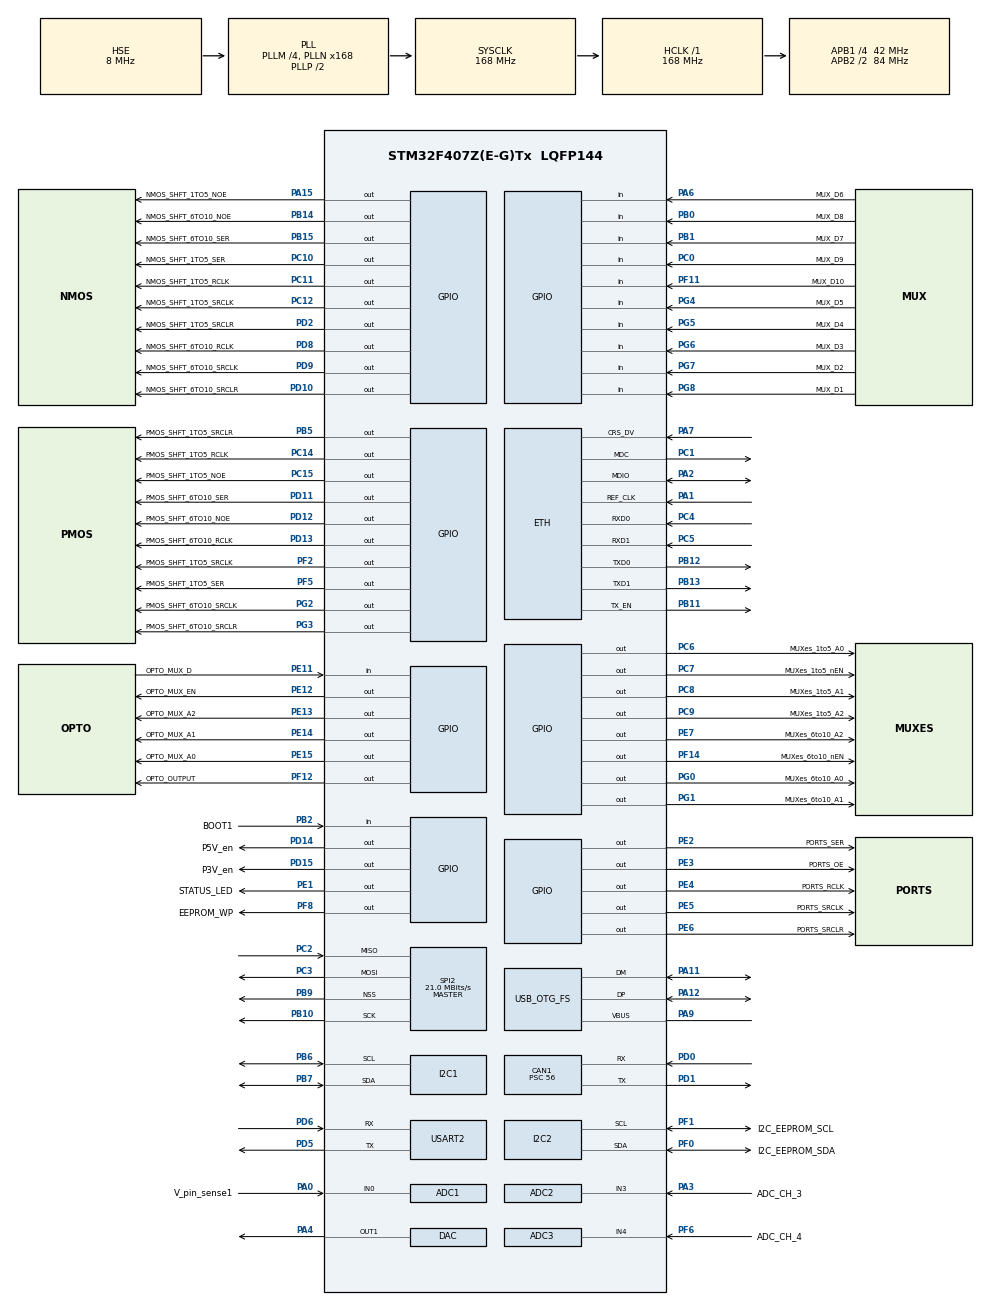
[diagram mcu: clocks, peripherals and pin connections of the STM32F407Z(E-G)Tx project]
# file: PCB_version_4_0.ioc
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ADC1.Channel-1\#ChannelRegularConversion=ADC_CHANNEL_0
ADC1.NbrOfConversionFlag=1
ADC1.Rank-1\#ChannelRegularConversion=1
ADC1.SamplingTime-1\#ChannelRegularConversion=ADC_SAMPLETIME_3CYCLES
ADC1.master=1
ADC2.Channel-2\#ChannelRegularConversion=ADC_CHANNEL_3
ADC2.NbrOfConversionFlag=1
ADC2.Rank-2\#ChannelRegularConversion=1
ADC2.SamplingTime-2\#ChannelRegularConversion=ADC_SAMPLETIME_3CYCLES
ADC3.Channel-1\#ChannelRegularConversion=ADC_CHANNEL_4
ADC3.NbrOfConversionFlag=1
ADC3.Rank-1\#ChannelRegularConversion=1
ADC3.SamplingTime-1\#ChannelRegularConversion=ADC_SAMPLETIME_3CYCLES
CAN1.CalculateBaudRate=249999
CAN1.CalculateTimeBit=4000
CAN1.CalculateTimeQuantum=1333.3333333333335
CAN1.Mode=CAN_MODE_LOOPBACK
CAN1.Prescaler=56
ETH.MACAddr=00\:80\:E1\:01\:23\:45
ETH.MediaInterface=HAL_ETH_RMII_MODE
ETH.PHY_Name_RMII=DP83848_PHY_ADDRESS
FREERTOS.Tasks01=defaultTask,0,8192,StartDefaultTask,Default,NULL,Dynamic,NULL,NULL
FREERTOS.configMINIMAL_STACK_SIZE=600
FREERTOS.configTOTAL_HEAP_SIZE=65536
FREERTOS.configUSE_NEWLIB_REENTRANT=1
LWIP.BSP.number=1
LWIP.CMSIS_VERSION-Enabled=1
LWIP.Version=v2.1.2_Cube
LWIP0.BSP.STBoard=false
LWIP0.BSP.api=BSP_COMPONENT_DRIVER
LWIP0.BSP.component=DP83848
LWIP0.BSP.instance=DP83848
LWIP0.BSP.name=Driver_PHY
LWIP0.BSP.semaphore=S_DP83848
LWIP0.BSP.solution=DP83848
Mcu.Family=STM32F4
Mcu.Name=STM32F407Z(E-G)Tx
Mcu.Package=LQFP144
NVIC.CAN1_RX0_IRQn=true\:5\:0\:false\:false\:true\:true\:true\:true\:true
NVIC.CAN1_RX1_IRQn=true\:5\:0\:false\:false\:true\:true\:true\:true\:true
NVIC.ETH_IRQn=true\:5\:0\:false\:false\:true\:true\:true\:true\:true
NVIC.OTG_FS_IRQn=true\:5\:0\:false\:false\:true\:true\:false\:true\:true
NVIC.PriorityGroup=NVIC_PRIORITYGROUP_4
NVIC.TIM1_TRG_COM_TIM11_IRQn=true\:5\:0\:false\:false\:true\:true\:true\:true\:true
NVIC.TIM8_TRG_COM_TIM14_IRQn=true\:15\:0\:false\:false\:true\:false\:false\:true\:true
NVIC.TimeBase=TIM8_TRG_COM_TIM14_IRQn
NVIC.TimeBaseIP=TIM14
PA0-WKUP.GPIO_Label=V_pin_sense1
PA0-WKUP.Signal=ADCx_IN0
PA1.Mode=RMII
PA1.Signal=ETH_REF_CLK
PA11.Mode=Device_Only
PA11.Signal=USB_OTG_FS_DM
PA12.Mode=Device_Only
PA12.Signal=USB_OTG_FS_DP
PA13.Mode=Trace_Asynchronous_SW
PA13.Signal=SYS_JTMS-SWDIO
PA14.Mode=Trace_Asynchronous_SW
PA14.Signal=SYS_JTCK-SWCLK
PA15.GPIO_Label=NMOS_SHFT_1TO5_NOE
PA15.Signal=GPIO_Output
PA2.Mode=RMII
PA2.Signal=ETH_MDIO
PA3.GPIO_Label=ADC_CH_3
PA3.Signal=ADCx_IN3
PA4.Signal=COMP_DAC1_group
PA6.GPIO_Label=MUX_D6
PA6.Signal=GPIO_Input
PA7.Mode=RMII
PA7.Signal=ETH_CRS_DV
PA9.Mode=Activate_VBUS
PA9.Signal=USB_OTG_FS_VBUS
PB0.GPIO_Label=MUX_D8
PB0.Signal=GPIO_Input
PB1.GPIO_Label=MUX_D7
PB1.Signal=GPIO_Input
PB10.Mode=Full_Duplex_Master
PB10.Signal=SPI2_SCK
PB11.Mode=RMII
PB11.Signal=ETH_TX_EN
PB12.Mode=RMII
PB12.Signal=ETH_TXD0
PB13.Mode=RMII
PB13.Signal=ETH_TXD1
PB14.GPIO_Label=NMOS_SHFT_6TO10_NOE
PB14.Signal=GPIO_Output
PB15.GPIO_Label=NMOS_SHFT_6TO10_SER
PB15.Signal=GPIO_Output
PB2.GPIO_Label=BOOT1
PB2.Signal=GPIO_Input
PB3.Mode=Trace_Asynchronous_SW
PB3.Signal=SYS_JTDO-SWO
PB5.GPIO_Label=PMOS_SHFT_1TO5_SRCLR
PB5.Signal=GPIO_Output
PB6.Mode=I2C
PB6.Signal=I2C1_SCL
PB7.Mode=I2C
PB7.Signal=I2C1_SDA
PB9.Mode=NSS_Signal_Hard_Output
PB9.Signal=SPI2_NSS
PC0.GPIO_Label=MUX_D9
PC0.Signal=GPIO_Input
PC1.Mode=RMII
PC1.Signal=ETH_MDC
PC10.GPIO_Label=NMOS_SHFT_1TO5_SER
PC10.Signal=GPIO_Output
PC11.GPIO_Label=NMOS_SHFT_1TO5_RCLK
PC11.Signal=GPIO_Output
PC12.GPIO_Label=NMOS_SHFT_1TO5_SRCLK
PC12.Signal=GPIO_Output
PC14-OSC32_IN.GPIO_Label=PMOS_SHFT_1TO5_RCLK
PC14-OSC32_IN.Signal=GPIO_Output
PC15-OSC32_OUT.GPIO_Label=PMOS_SHFT_1TO5_NOE
PC15-OSC32_OUT.Signal=GPIO_Output
PC2.Mode=Full_Duplex_Master
PC2.Signal=SPI2_MISO
PC3.Mode=Full_Duplex_Master
PC3.Signal=SPI2_MOSI
PC4.Mode=RMII
PC4.Signal=ETH_RXD0
PC5.Mode=RMII
PC5.Signal=ETH_RXD1
PC6.GPIO_Label=MUXes_1to5_A0
PC6.Signal=GPIO_Output
PC7.GPIO_Label=MUXes_1to5_nEN
PC7.Signal=GPIO_Output
PC8.GPIO_Label=MUXes_1to5_A1
PC8.Signal=GPIO_Output
PC9.GPIO_Label=MUXes_1to5_A2
PC9.Signal=GPIO_Output
PD0.GPIO_PuPd=GPIO_NOPULL
PD0.Mode=CAN_Activate
PD0.Signal=CAN1_RX
PD1.GPIO_PuPd=GPIO_NOPULL
PD1.Mode=CAN_Activate
PD1.Signal=CAN1_TX
PD10.GPIO_Label=NMOS_SHFT_6TO10_SRCLR
PD10.Signal=GPIO_Output
PD11.GPIO_Label=PMOS_SHFT_6TO10_SER
PD11.Signal=GPIO_Output
PD12.GPIO_Label=PMOS_SHFT_6TO10_NOE
PD12.Signal=GPIO_Output
PD13.GPIO_Label=PMOS_SHFT_6TO10_RCLK
PD13.Signal=GPIO_Output
PD14.GPIO_Label=P5V_en
PD14.Signal=GPIO_Output
PD15.GPIO_Label=P3V_en
PD15.Signal=GPIO_Output
PD2.GPIO_Label=NMOS_SHFT_1TO5_SRCLR
PD2.Signal=GPIO_Output
PD5.Mode=Asynchronous
PD5.Signal=USART2_TX
PD6.Mode=Asynchronous
PD6.Signal=USART2_RX
PD8.GPIO_Label=NMOS_SHFT_6TO10_RCLK
PD8.Signal=GPIO_Output
PD9.GPIO_Label=NMOS_SHFT_6TO10_SRCLK
PD9.Signal=GPIO_Output
PE1.GPIO_Label=STATUS_LED
PE1.Signal=GPIO_Output
PE11.GPIO_Label=OPTO_MUX_D
PE11.GPIO_PuPd=GPIO_NOPULL
PE11.Signal=GPIO_Input
PE12.GPIO_Label=OPTO_MUX_EN
PE12.GPIO_PuPd=GPIO_NOPULL
PE12.Signal=GPIO_Output
PE13.GPIO_Label=OPTO_MUX_A2
PE13.GPIO_Speed=GPIO_SPEED_FREQ_MEDIUM
PE13.Signal=GPIO_Output
PE14.GPIO_Label=OPTO_MUX_A1
PE14.GPIO_Speed=GPIO_SPEED_FREQ_MEDIUM
PE14.Signal=GPIO_Output
PE15.GPIO_Label=OPTO_MUX_A0
PE15.GPIO_Speed=GPIO_SPEED_FREQ_MEDIUM
PE15.Signal=GPIO_Output
PE2.GPIO_Label=PORTS_SER
PE2.Signal=GPIO_Output
PE3.GPIO_Label=PORTS_OE
PE3.Signal=GPIO_Output
PE4.GPIO_Label=PORTS_RCLK
PE4.Signal=GPIO_Output
PE5.GPIO_Label=PORTS_SRCLK
PE5.Signal=GPIO_Output
PE6.GPIO_Label=PORTS_SRCLR
PE6.Signal=GPIO_Output
PE7.GPIO_Label=MUXes_6to10_A2
PE7.Signal=GPIO_Output
PF0.GPIO_Label=I2C_EEPROM_SDA
PF0.Mode=I2C
PF0.Signal=I2C2_SDA
PF1.GPIO_Label=I2C_EEPROM_SCL
PF1.Mode=I2C
PF1.Signal=I2C2_SCL
PF11.GPIO_Label=MUX_D10
PF11.Signal=GPIO_Input
PF12.GPIO_Label=OPTO_OUTPUT
PF12.Signal=GPIO_Output
PF14.GPIO_Label=MUXes_6to10_nEN
PF14.Signal=GPIO_Output
PF2.GPIO_Label=PMOS_SHFT_1TO5_SRCLK
PF2.Signal=GPIO_Output
PF5.GPIO_Label=PMOS_SHFT_1TO5_SER
PF5.Signal=GPIO_Output
PF6.GPIO_Label=ADC_CH_4
PF6.Mode=IN4
PF6.Signal=ADC3_IN4
PF8.GPIO_Label=EEPROM_WP
PF8.Signal=GPIO_Output
PG0.GPIO_Label=MUXes_6to10_A0
PG0.Signal=GPIO_Output
PG1.GPIO_Label=MUXes_6to10_A1
PG1.Signal=GPIO_Output
PG2.GPIO_Label=PMOS_SHFT_6TO10_SRCLK
PG2.Signal=GPIO_Output
PG3.GPIO_Label=PMOS_SHFT_6TO10_SRCLR
PG3.Signal=GPIO_Output
PG4.GPIO_Label=MUX_D5
PG4.Signal=GPIO_Input
PG5.GPIO_Label=MUX_D4
PG5.Signal=GPIO_Input
PG6.GPIO_Label=MUX_D3
PG6.Signal=GPIO_Input
PG7.GPIO_Label=MUX_D2
PG7.Signal=GPIO_Input
PG8.GPIO_Label=MUX_D1
PG8.Signal=GPIO_Input
PH0-OSC_IN.Mode=HSE-External-Oscillator
PH0-OSC_IN.Signal=RCC_OSC_IN
PH1-OSC_OUT.Mode=HSE-External-Oscillator
PH1-OSC_OUT.Signal=RCC_OSC_OUT
ProjectManager.HeapSize=0x200
ProjectManager.StackSize=0x400
ProjectManager.TargetToolchain=Makefile
RCC.48MHZClocksFreq_Value=48000000
RCC.AHBFreq_Value=168000000
RCC.APB1CLKDivider=RCC_HCLK_DIV4
RCC.APB1Freq_Value=42000000
RCC.APB1TimFreq_Value=84000000
RCC.APB2CLKDivider=RCC_HCLK_DIV2
RCC.APB2Freq_Value=84000000
RCC.APB2TimFreq_Value=168000000
RCC.CortexFreq_Value=168000000
RCC.HCLKFreq_Value=168000000
RCC.HSE_VALUE=8000000
RCC.HSI_VALUE=16000000
RCC.LSE_VALUE=32768
RCC.PLLM=4
RCC.PLLN=168
RCC.PLLQ=7
RCC.RCC_RTC_Clock_Source=RCC_RTCCLKSOURCE_LSE
RCC.RCC_RTC_Clock_SourceVirtual=RCC_RTCCLKSOURCE_LSE
RCC.RCC_RTC_Clock_Source_FROM_HSE=RCC_RTCCLKSOURCE_HSE_DIV9
RCC.SYSCLKFreq_VALUE=168000000
RCC.SYSCLKSource=RCC_SYSCLKSOURCE_PLLCLK
RCC.VCOOutputFreq_Value=336000000
SH.ADCx_IN0.0=ADC1_IN0,IN0
SH.ADCx_IN3.0=ADC2_IN3,IN3
SH.COMP_DAC1_group.0=DAC_OUT1,DAC_OUT1
SPI2.BaudRatePrescaler=SPI_BAUDRATEPRESCALER_2
SPI2.CalculateBaudRate=21.0 MBits/s
SPI2.Direction=SPI_DIRECTION_2LINES
SPI2.Mode=SPI_MODE_MASTER
SPI2.VirtualNSS=VM_NSSHARD
SPI2.VirtualType=VM_MASTER
TIM11.AutoReloadPreload=TIM_AUTORELOAD_PRELOAD_ENABLE
TIM11.Period=240-1
USART2.VirtualMode=VM_ASYNC
USB_DEVICE.CLASS_NAME_FS=CDC
USB_DEVICE.VirtualMode-CDC_FS=Cdc
USB_DEVICE.VirtualModeFS=Cdc_FS
USB_OTG_FS.VirtualMode=Device_Only
VP_FREERTOS_VS_CMSIS_V1.Mode=CMSIS_V1
VP_LWIP_VS_Enabled.Mode=Enabled
VP_SYS_VS_tim14.Mode=TIM14
VP_TIM11_VS_ClockSourceINT.Mode=Enable_Timer
VP_USB_DEVICE_VS_USB_DEVICE_CDC_FS.Mode=CDC_FS
board=custom

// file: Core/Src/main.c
/* USER CODE BEGIN Header */
/**
  ******************************************************************************
  * @file           : main.c
  * @brief          : Main program body
  ******************************************************************************
  * @attention
  *
  * Copyright (c) 2023 STMicroelectronics.
  * All rights reserved.
  *
  * This software is licensed under terms that can be found in the LICENSE file
  * in the root directory of this software component.
  * If no LICENSE file comes with this software, it is provided AS-IS.
  *
  ******************************************************************************
  */
/* USER CODE END Header */
#include "main.h"
#include "cmsis_os.h"
#include "lwip.h"
#include "usb_device.h"

/* USER CODE BEGIN Includes */
#include "usbd_cdc_if.h"
#include "stdio.h"
#include "tcpserver.h"
#include "globals.h"
/* USER CODE END Includes */

/* USER CODE BEGIN PM */
CAN_TxHeaderTypeDef CanTxHeader;
CAN_RxHeaderTypeDef CanRxHeader;
uint32_t CanTxMailbox;
uint8_t CanTxData[8];
uint8_t CanRxData[8];

HAL_StatusTypeDef status;
uint32_t Reg_Val;

/* USER CODE END PM */

ADC_HandleTypeDef hadc1;
ADC_HandleTypeDef hadc2;
ADC_HandleTypeDef hadc3;

CAN_HandleTypeDef hcan1;

DAC_HandleTypeDef hdac;

I2C_HandleTypeDef hi2c1;
I2C_HandleTypeDef hi2c2;

SPI_HandleTypeDef hspi2;

TIM_HandleTypeDef htim11;

UART_HandleTypeDef huart2;

osThreadId defaultTaskHandle;
/* USER CODE BEGIN PV */
extern int tcpecho_init();

/* USER CODE END PV */

void SystemClock_Config(void);
static void MX_GPIO_Init(void);
static void MX_ADC1_Init(void);
static void MX_ADC2_Init(void);
static void MX_DAC_Init(void);
static void MX_SPI2_Init(void);
static void MX_ADC3_Init(void);
static void MX_CAN1_Init(void);
static void MX_I2C1_Init(void);
static void MX_USART2_UART_Init(void);
static void MX_I2C2_Init(void);
static void MX_TIM11_Init(void);
void StartDefaultTask(void const * argument);

/* USER CODE BEGIN PFP */
//Redriect printf to USB CDC
int _write(int file, char *ptr, int len)
{
  CDC_Transmit_FS((uint8_t*)ptr, len);
  return len;
}

//overide HAL_CAN_RxFifo0MsgPendingCallback
__weak void HAL_CAN_RxFifo0MsgPendingCallback(CAN_HandleTypeDef *hcan)
{
  printf("CAN RX Callback\n");
}

/* USER CODE END PFP */

int main(void)
{

  /* MCU Configuration--------------------------------------------------------*/

  /* Reset of all peripherals, Initializes the Flash interface and the Systick. */
  HAL_Init();

  /* Configure the system clock */
  SystemClock_Config();

  /* Initialize all configured peripherals */
  MX_GPIO_Init();
  MX_ADC1_Init();
  MX_ADC2_Init();
  MX_DAC_Init();
  MX_SPI2_Init();
  MX_ADC3_Init();
  MX_CAN1_Init();
  MX_I2C1_Init();
  MX_USART2_UART_Init();
  MX_I2C2_Init();
  MX_TIM11_Init();
  /* USER CODE BEGIN 2 */
  HAL_TIM_Base_Start_IT(&htim11);
  /* USER CODE END 2 */

  /* Create the thread(s) */
  /* definition and creation of defaultTask */
  osThreadDef(defaultTask, StartDefaultTask, osPriorityNormal, 0, 8192);
  defaultTaskHandle = osThreadCreate(osThread(defaultTask), NULL);

  /* Start scheduler */
  osKernelStart();
  /* We should never get here as control is now taken by the scheduler */
  /* Infinite loop */
  while (1)
  {

  }
}

void SystemClock_Config(void)
{
  RCC_OscInitTypeDef RCC_OscInitStruct = {0};
  RCC_ClkInitTypeDef RCC_ClkInitStruct = {0};

  /** Configure the main internal regulator output voltage
  */
  __HAL_RCC_PWR_CLK_ENABLE();
  __HAL_PWR_VOLTAGESCALING_CONFIG(PWR_REGULATOR_VOLTAGE_SCALE1);

  /** Initializes the RCC Oscillators according to the specified parameters
  * in the RCC_OscInitTypeDef structure.
  */
  RCC_OscInitStruct.OscillatorType = RCC_OSCILLATORTYPE_HSE;
  RCC_OscInitStruct.HSEState = RCC_HSE_ON;
  RCC_OscInitStruct.PLL.PLLState = RCC_PLL_ON;
  RCC_OscInitStruct.PLL.PLLSource = RCC_PLLSOURCE_HSE;
  RCC_OscInitStruct.PLL.PLLM = 4;
  RCC_OscInitStruct.PLL.PLLN = 168;
  RCC_OscInitStruct.PLL.PLLP = RCC_PLLP_DIV2;
  RCC_OscInitStruct.PLL.PLLQ = 7;
  if (HAL_RCC_OscConfig(&RCC_OscInitStruct) != HAL_OK)
  {
    Error_Handler();
  }

  /** Initializes the CPU, AHB and APB buses clocks
  */
  RCC_ClkInitStruct.ClockType = RCC_CLOCKTYPE_HCLK|RCC_CLOCKTYPE_SYSCLK
                              |RCC_CLOCKTYPE_PCLK1|RCC_CLOCKTYPE_PCLK2;
  RCC_ClkInitStruct.SYSCLKSource = RCC_SYSCLKSOURCE_PLLCLK;
  RCC_ClkInitStruct.AHBCLKDivider = RCC_SYSCLK_DIV1;
  RCC_ClkInitStruct.APB1CLKDivider = RCC_HCLK_DIV4;
  RCC_ClkInitStruct.APB2CLKDivider = RCC_HCLK_DIV2;

  if (HAL_RCC_ClockConfig(&RCC_ClkInitStruct, FLASH_LATENCY_5) != HAL_OK)
  {
    Error_Handler();
  }
}

static void MX_ADC1_Init(void)
{

  ADC_ChannelConfTypeDef sConfig = {0};

  /** Configure the global features of the ADC (Clock, Resolution, Data Alignment and number of conversion)
  */
  hadc1.Instance = ADC1;
  hadc1.Init.ClockPrescaler = ADC_CLOCK_SYNC_PCLK_DIV4;
  hadc1.Init.Resolution = ADC_RESOLUTION_12B;
  hadc1.Init.ScanConvMode = DISABLE;
  hadc1.Init.ContinuousConvMode = DISABLE;
  hadc1.Init.DiscontinuousConvMode = DISABLE;
  hadc1.Init.ExternalTrigConvEdge = ADC_EXTERNALTRIGCONVEDGE_NONE;
  hadc1.Init.ExternalTrigConv = ADC_SOFTWARE_START;
  hadc1.Init.DataAlign = ADC_DATAALIGN_RIGHT;
  hadc1.Init.NbrOfConversion = 1;
  hadc1.Init.DMAContinuousRequests = DISABLE;
  hadc1.Init.EOCSelection = ADC_EOC_SINGLE_CONV;
  if (HAL_ADC_Init(&hadc1) != HAL_OK)
  {
    Error_Handler();
  }

  /** Configure for the selected ADC regular channel its corresponding rank in the sequencer and its sample time.
  */
  sConfig.Channel = ADC_CHANNEL_0;
  sConfig.Rank = 1;
  sConfig.SamplingTime = ADC_SAMPLETIME_3CYCLES;
  if (HAL_ADC_ConfigChannel(&hadc1, &sConfig) != HAL_OK)
  {
    Error_Handler();
  }

}

static void MX_ADC2_Init(void)
{

  ADC_ChannelConfTypeDef sConfig = {0};

  /** Configure the global features of the ADC (Clock, Resolution, Data Alignment and number of conversion)
  */
  hadc2.Instance = ADC2;
  hadc2.Init.ClockPrescaler = ADC_CLOCK_SYNC_PCLK_DIV4;
  hadc2.Init.Resolution = ADC_RESOLUTION_12B;
  hadc2.Init.ScanConvMode = DISABLE;
  hadc2.Init.ContinuousConvMode = DISABLE;
  hadc2.Init.DiscontinuousConvMode = DISABLE;
  hadc2.Init.ExternalTrigConvEdge = ADC_EXTERNALTRIGCONVEDGE_NONE;
  hadc2.Init.ExternalTrigConv = ADC_SOFTWARE_START;
  hadc2.Init.DataAlign = ADC_DATAALIGN_RIGHT;
  hadc2.Init.NbrOfConversion = 1;
  hadc2.Init.DMAContinuousRequests = DISABLE;
  hadc2.Init.EOCSelection = ADC_EOC_SINGLE_CONV;
  if (HAL_ADC_Init(&hadc2) != HAL_OK)
  {
    Error_Handler();
  }

  /** Configure for the selected ADC regular channel its corresponding rank in the sequencer and its sample time.
  */
  sConfig.Channel = ADC_CHANNEL_3;
  sConfig.Rank = 1;
  sConfig.SamplingTime = ADC_SAMPLETIME_3CYCLES;
  if (HAL_ADC_ConfigChannel(&hadc2, &sConfig) != HAL_OK)
  {
    Error_Handler();
  }

}

static void MX_ADC3_Init(void)
{

  ADC_ChannelConfTypeDef sConfig = {0};

  /** Configure the global features of the ADC (Clock, Resolution, Data Alignment and number of conversion)
  */
  hadc3.Instance = ADC3;
  hadc3.Init.ClockPrescaler = ADC_CLOCK_SYNC_PCLK_DIV4;
  hadc3.Init.Resolution = ADC_RESOLUTION_12B;
  hadc3.Init.ScanConvMode = DISABLE;
  hadc3.Init.ContinuousConvMode = DISABLE;
  hadc3.Init.DiscontinuousConvMode = DISABLE;
  hadc3.Init.ExternalTrigConvEdge = ADC_EXTERNALTRIGCONVEDGE_NONE;
  hadc3.Init.ExternalTrigConv = ADC_SOFTWARE_START;
  hadc3.Init.DataAlign = ADC_DATAALIGN_RIGHT;
  hadc3.Init.NbrOfConversion = 1;
  hadc3.Init.DMAContinuousRequests = DISABLE;
  hadc3.Init.EOCSelection = ADC_EOC_SINGLE_CONV;
  if (HAL_ADC_Init(&hadc3) != HAL_OK)
  {
    Error_Handler();
  }

  /** Configure for the selected ADC regular channel its corresponding rank in the sequencer and its sample time.
  */
  sConfig.Channel = ADC_CHANNEL_4;
  sConfig.Rank = 1;
  sConfig.SamplingTime = ADC_SAMPLETIME_3CYCLES;
  if (HAL_ADC_ConfigChannel(&hadc3, &sConfig) != HAL_OK)
  {
    Error_Handler();
  }

}

static void MX_CAN1_Init(void)
{

  hcan1.Instance = CAN1;
  hcan1.Init.Prescaler = 56;
  hcan1.Init.Mode = CAN_MODE_LOOPBACK;
  hcan1.Init.SyncJumpWidth = CAN_SJW_1TQ;
  hcan1.Init.TimeSeg1 = CAN_BS1_1TQ;
  hcan1.Init.TimeSeg2 = CAN_BS2_1TQ;
  hcan1.Init.TimeTriggeredMode = DISABLE;
  hcan1.Init.AutoBusOff = DISABLE;
  hcan1.Init.AutoWakeUp = DISABLE;
  hcan1.Init.AutoRetransmission = DISABLE;
  hcan1.Init.ReceiveFifoLocked = DISABLE;
  hcan1.Init.TransmitFifoPriority = DISABLE;
  if (HAL_CAN_Init(&hcan1) != HAL_OK)
  {
    Error_Handler();
  }
  /* USER CODE BEGIN CAN1_Init 2 */
  CAN_FilterTypeDef canFilterConfig;
  canFilterConfig.FilterActivation = CAN_FILTER_ENABLE;
  canFilterConfig.FilterBank = 10;  // anything between 0 to SlaveStartFilterBank
  canFilterConfig.FilterFIFOAssignment = CAN_RX_FIFO0;
  canFilterConfig.FilterIdHigh = 0;
  canFilterConfig.FilterIdLow = 0x0;
  canFilterConfig.FilterMaskIdHigh = 0x0;
  canFilterConfig.FilterMaskIdLow = 0x0000;
  canFilterConfig.FilterMode = CAN_FILTERMODE_IDMASK;
  canFilterConfig.FilterScale = CAN_FILTERSCALE_32BIT;
  canFilterConfig.SlaveStartFilterBank = 0;  // 13 to 27 are assigned to slave CAN (CAN 2) OR 0 to 12 are assgned to CAN1

  HAL_CAN_ConfigFilter(&hcan1, &canFilterConfig);

  /* USER CODE END CAN1_Init 2 */

}

static void MX_DAC_Init(void)
{

  DAC_ChannelConfTypeDef sConfig = {0};

  /** DAC Initialization
  */
  hdac.Instance = DAC;
  if (HAL_DAC_Init(&hdac) != HAL_OK)
  {
    Error_Handler();
  }

  /** DAC channel OUT1 config
  */
  sConfig.DAC_Trigger = DAC_TRIGGER_NONE;
  sConfig.DAC_OutputBuffer = DAC_OUTPUTBUFFER_ENABLE;
  if (HAL_DAC_ConfigChannel(&hdac, &sConfig, DAC_CHANNEL_1) != HAL_OK)
  {
    Error_Handler();
  }
  /* USER CODE BEGIN DAC_Init 2 */
  HAL_DAC_Start(&hdac, DAC_CHANNEL_1);
  /* USER CODE END DAC_Init 2 */

}

static void MX_I2C1_Init(void)
{

  hi2c1.Instance = I2C1;
  hi2c1.Init.ClockSpeed = 100000;
  hi2c1.Init.DutyCycle = I2C_DUTYCYCLE_2;
  hi2c1.Init.OwnAddress1 = 0;
  hi2c1.Init.AddressingMode = I2C_ADDRESSINGMODE_7BIT;
  hi2c1.Init.DualAddressMode = I2C_DUALADDRESS_DISABLE;
  hi2c1.Init.OwnAddress2 = 0;
  hi2c1.Init.GeneralCallMode = I2C_GENERALCALL_DISABLE;
  hi2c1.Init.NoStretchMode = I2C_NOSTRETCH_DISABLE;
  if (HAL_I2C_Init(&hi2c1) != HAL_OK)
  {
    Error_Handler();
  }

}

static void MX_I2C2_Init(void)
{

  hi2c2.Instance = I2C2;
  hi2c2.Init.ClockSpeed = 100000;
  hi2c2.Init.DutyCycle = I2C_DUTYCYCLE_2;
  hi2c2.Init.OwnAddress1 = 0;
  hi2c2.Init.AddressingMode = I2C_ADDRESSINGMODE_7BIT;
  hi2c2.Init.DualAddressMode = I2C_DUALADDRESS_DISABLE;
  hi2c2.Init.OwnAddress2 = 0;
  hi2c2.Init.GeneralCallMode = I2C_GENERALCALL_DISABLE;
  hi2c2.Init.NoStretchMode = I2C_NOSTRETCH_DISABLE;
  if (HAL_I2C_Init(&hi2c2) != HAL_OK)
  {
    Error_Handler();
  }

}

static void MX_SPI2_Init(void)
{

  /* SPI2 parameter configuration*/
  hspi2.Instance = SPI2;
  hspi2.Init.Mode = SPI_MODE_MASTER;
  hspi2.Init.Direction = SPI_DIRECTION_2LINES;
  hspi2.Init.DataSize = SPI_DATASIZE_8BIT;
  hspi2.Init.CLKPolarity = SPI_POLARITY_LOW;
  hspi2.Init.CLKPhase = SPI_PHASE_1EDGE;
  hspi2.Init.NSS = SPI_NSS_HARD_OUTPUT;
  hspi2.Init.BaudRatePrescaler = SPI_BAUDRATEPRESCALER_2;
  hspi2.Init.FirstBit = SPI_FIRSTBIT_MSB;
  hspi2.Init.TIMode = SPI_TIMODE_DISABLE;
  hspi2.Init.CRCCalculation = SPI_CRCCALCULATION_DISABLE;
  hspi2.Init.CRCPolynomial = 10;
  if (HAL_SPI_Init(&hspi2) != HAL_OK)
  {
    Error_Handler();
  }

}

static void MX_TIM11_Init(void)
{

  htim11.Instance = TIM11;
  htim11.Init.Prescaler = 0;
  htim11.Init.CounterMode = TIM_COUNTERMODE_UP;
  htim11.Init.Period = 240-1;
  htim11.Init.ClockDivision = TIM_CLOCKDIVISION_DIV1;
  htim11.Init.AutoReloadPreload = TIM_AUTORELOAD_PRELOAD_ENABLE;
  if (HAL_TIM_Base_Init(&htim11) != HAL_OK)
  {
    Error_Handler();
  }

}

static void MX_USART2_UART_Init(void)
{

  huart2.Instance = USART2;
  huart2.Init.BaudRate = 115200;
  huart2.Init.WordLength = UART_WORDLENGTH_8B;
  huart2.Init.StopBits = UART_STOPBITS_1;
  huart2.Init.Parity = UART_PARITY_NONE;
  huart2.Init.Mode = UART_MODE_TX_RX;
  huart2.Init.HwFlowCtl = UART_HWCONTROL_NONE;
  huart2.Init.OverSampling = UART_OVERSAMPLING_16;
  if (HAL_UART_Init(&huart2) != HAL_OK)
  {
    Error_Handler();
  }

}

static void MX_GPIO_Init(void)
{
  GPIO_InitTypeDef GPIO_InitStruct = {0};

  /* GPIO Ports Clock Enable */
  __HAL_RCC_GPIOE_CLK_ENABLE();
  __HAL_RCC_GPIOC_CLK_ENABLE();
  __HAL_RCC_GPIOF_CLK_ENABLE();
  __HAL_RCC_GPIOH_CLK_ENABLE();
  __HAL_RCC_GPIOA_CLK_ENABLE();
  __HAL_RCC_GPIOB_CLK_ENABLE();
  __HAL_RCC_GPIOG_CLK_ENABLE();
  __HAL_RCC_GPIOD_CLK_ENABLE();

  /*Configure GPIO pin Output Level */
  HAL_GPIO_WritePin(GPIOE, PORTS_SER_Pin|PORTS_OE_Pin|PORTS_RCLK_Pin|PORTS_SRCLK_Pin
                          |PORTS_SRCLR_Pin|MUXes_6to10_A2_Pin|OPTO_MUX_EN_Pin|OPTO_MUX_A2_Pin
                          |OPTO_MUX_A1_Pin|OPTO_MUX_A0_Pin|STATUS_LED_Pin, GPIO_PIN_RESET);

  /*Configure GPIO pin Output Level */
  HAL_GPIO_WritePin(GPIOC, PMOS_SHFT_1TO5_RCLK_Pin|PMOS_SHFT_1TO5_NOE_Pin|MUXes_1to5_A0_Pin|MUXes_1to5_nEN_Pin
                          |MUXes_1to5_A1_Pin|MUXes_1to5_A2_Pin|NMOS_SHFT_1TO5_SER_Pin|NMOS_SHFT_1TO5_RCLK_Pin
                          |NMOS_SHFT_1TO5_SRCLK_Pin, GPIO_PIN_RESET);

  /*Configure GPIO pin Output Level */
  HAL_GPIO_WritePin(GPIOF, PMOS_SHFT_1TO5_SRCLK_Pin|PMOS_SHFT_1TO5_SER_Pin|EEPROM_WP_Pin|OPTO_OUTPUT_Pin
                          |MUXes_6to10_nEN_Pin, GPIO_PIN_RESET);

  /*Configure GPIO pin Output Level */
  HAL_GPIO_WritePin(GPIOG, MUXes_6to10_A0_Pin|MUXes_6to10_A1_Pin|PMOS_SHFT_6TO10_SRCLK_Pin|PMOS_SHFT_6TO10_SRCLR_Pin, GPIO_PIN_RESET);

  /*Configure GPIO pin Output Level */
  HAL_GPIO_WritePin(GPIOB, NMOS_SHFT_6TO10_NOE_Pin|NMOS_SHFT_6TO10_SER_Pin|PMOS_SHFT_1TO5_SRCLR_Pin, GPIO_PIN_RESET);

  /*Configure GPIO pin Output Level */
  HAL_GPIO_WritePin(GPIOD, NMOS_SHFT_6TO10_RCLK_Pin|NMOS_SHFT_6TO10_SRCLK_Pin|NMOS_SHFT_6TO10_SRCLR_Pin|PMOS_SHFT_6TO10_SER_Pin
                          |PMOS_SHFT_6TO10_NOE_Pin|PMOS_SHFT_6TO10_RCLK_Pin|P5V_en_Pin|P3V_en_Pin
                          |NMOS_SHFT_1TO5_SRCLR_Pin, GPIO_PIN_RESET);

  /*Configure GPIO pin Output Level */
  HAL_GPIO_WritePin(NMOS_SHFT_1TO5_NOE_GPIO_Port, NMOS_SHFT_1TO5_NOE_Pin, GPIO_PIN_RESET);

  /*Configure GPIO pins : PORTS_SER_Pin PORTS_OE_Pin PORTS_RCLK_Pin PORTS_SRCLK_Pin
                           PORTS_SRCLR_Pin MUXes_6to10_A2_Pin OPTO_MUX_EN_Pin STATUS_LED_Pin */
  GPIO_InitStruct.Pin = PORTS_SER_Pin|PORTS_OE_Pin|PORTS_RCLK_Pin|PORTS_SRCLK_Pin
                          |PORTS_SRCLR_Pin|MUXes_6to10_A2_Pin|OPTO_MUX_EN_Pin|STATUS_LED_Pin;
  GPIO_InitStruct.Mode = GPIO_MODE_OUTPUT_PP;
  GPIO_InitStruct.Pull = GPIO_NOPULL;
  GPIO_InitStruct.Speed = GPIO_SPEED_FREQ_LOW;
  HAL_GPIO_Init(GPIOE, &GPIO_InitStruct);

  /*Configure GPIO pins : PMOS_SHFT_1TO5_RCLK_Pin PMOS_SHFT_1TO5_NOE_Pin MUXes_1to5_A0_Pin MUXes_1to5_nEN_Pin
                           MUXes_1to5_A1_Pin MUXes_1to5_A2_Pin NMOS_SHFT_1TO5_SER_Pin NMOS_SHFT_1TO5_RCLK_Pin
                           NMOS_SHFT_1TO5_SRCLK_Pin */
  GPIO_InitStruct.Pin = PMOS_SHFT_1TO5_RCLK_Pin|PMOS_SHFT_1TO5_NOE_Pin|MUXes_1to5_A0_Pin|MUXes_1to5_nEN_Pin
                          |MUXes_1to5_A1_Pin|MUXes_1to5_A2_Pin|NMOS_SHFT_1TO5_SER_Pin|NMOS_SHFT_1TO5_RCLK_Pin
                          |NMOS_SHFT_1TO5_SRCLK_Pin;
  GPIO_InitStruct.Mode = GPIO_MODE_OUTPUT_PP;
  GPIO_InitStruct.Pull = GPIO_NOPULL;
  GPIO_InitStruct.Speed = GPIO_SPEED_FREQ_LOW;
  HAL_GPIO_Init(GPIOC, &GPIO_InitStruct);

  /*Configure GPIO pins : PMOS_SHFT_1TO5_SRCLK_Pin PMOS_SHFT_1TO5_SER_Pin EEPROM_WP_Pin OPTO_OUTPUT_Pin
                           MUXes_6to10_nEN_Pin */
  GPIO_InitStruct.Pin = PMOS_SHFT_1TO5_SRCLK_Pin|PMOS_SHFT_1TO5_SER_Pin|EEPROM_WP_Pin|OPTO_OUTPUT_Pin
                          |MUXes_6to10_nEN_Pin;
  GPIO_InitStruct.Mode = GPIO_MODE_OUTPUT_PP;
  GPIO_InitStruct.Pull = GPIO_NOPULL;
  GPIO_InitStruct.Speed = GPIO_SPEED_FREQ_LOW;
  HAL_GPIO_Init(GPIOF, &GPIO_InitStruct);

  /*Configure GPIO pin : MUX_D9_Pin */
  GPIO_InitStruct.Pin = MUX_D9_Pin;
  GPIO_InitStruct.Mode = GPIO_MODE_INPUT;
  GPIO_InitStruct.Pull = GPIO_NOPULL;
  HAL_GPIO_Init(MUX_D9_GPIO_Port, &GPIO_InitStruct);

  /*Configure GPIO pin : MUX_D6_Pin */
  GPIO_InitStruct.Pin = MUX_D6_Pin;
  GPIO_InitStruct.Mode = GPIO_MODE_INPUT;
  GPIO_InitStruct.Pull = GPIO_NOPULL;
  HAL_GPIO_Init(MUX_D6_GPIO_Port, &GPIO_InitStruct);

  /*Configure GPIO pins : MUX_D8_Pin MUX_D7_Pin BOOT1_Pin */
  GPIO_InitStruct.Pin = MUX_D8_Pin|MUX_D7_Pin|BOOT1_Pin;
  GPIO_InitStruct.Mode = GPIO_MODE_INPUT;
  GPIO_InitStruct.Pull = GPIO_NOPULL;
  HAL_GPIO_Init(GPIOB, &GPIO_InitStruct);

  /*Configure GPIO pin : MUX_D10_Pin */
  GPIO_InitStruct.Pin = MUX_D10_Pin;
  GPIO_InitStruct.Mode = GPIO_MODE_INPUT;
  GPIO_InitStruct.Pull = GPIO_NOPULL;
  HAL_GPIO_Init(MUX_D10_GPIO_Port, &GPIO_InitStruct);

  /*Configure GPIO pins : MUXes_6to10_A0_Pin MUXes_6to10_A1_Pin PMOS_SHFT_6TO10_SRCLK_Pin PMOS_SHFT_6TO10_SRCLR_Pin */
  GPIO_InitStruct.Pin = MUXes_6to10_A0_Pin|MUXes_6to10_A1_Pin|PMOS_SHFT_6TO10_SRCLK_Pin|PMOS_SHFT_6TO10_SRCLR_Pin;
  GPIO_InitStruct.Mode = GPIO_MODE_OUTPUT_PP;
  GPIO_InitStruct.Pull = GPIO_NOPULL;
  GPIO_InitStruct.Speed = GPIO_SPEED_FREQ_LOW;
  HAL_GPIO_Init(GPIOG, &GPIO_InitStruct);

  /*Configure GPIO pin : OPTO_MUX_D_Pin */
  GPIO_InitStruct.Pin = OPTO_MUX_D_Pin;
  GPIO_InitStruct.Mode = GPIO_MODE_INPUT;
  GPIO_InitStruct.Pull = GPIO_NOPULL;
  HAL_GPIO_Init(OPTO_MUX_D_GPIO_Port, &GPIO_InitStruct);

  /*Configure GPIO pins : OPTO_MUX_A2_Pin OPTO_MUX_A1_Pin OPTO_MUX_A0_Pin */
  GPIO_InitStruct.Pin = OPTO_MUX_A2_Pin|OPTO_MUX_A1_Pin|OPTO_MUX_A0_Pin;
  GPIO_InitStruct.Mode = GPIO_MODE_OUTPUT_PP;
  GPIO_InitStruct.Pull = GPIO_NOPULL;
  GPIO_InitStruct.Speed = GPIO_SPEED_FREQ_MEDIUM;
  HAL_GPIO_Init(GPIOE, &GPIO_InitStruct);

  /*Configure GPIO pins : NMOS_SHFT_6TO10_NOE_Pin NMOS_SHFT_6TO10_SER_Pin PMOS_SHFT_1TO5_SRCLR_Pin */
  GPIO_InitStruct.Pin = NMOS_SHFT_6TO10_NOE_Pin|NMOS_SHFT_6TO10_SER_Pin|PMOS_SHFT_1TO5_SRCLR_Pin;
  GPIO_InitStruct.Mode = GPIO_MODE_OUTPUT_PP;
  GPIO_InitStruct.Pull = GPIO_NOPULL;
  GPIO_InitStruct.Speed = GPIO_SPEED_FREQ_LOW;
  HAL_GPIO_Init(GPIOB, &GPIO_InitStruct);

  /*Configure GPIO pins : NMOS_SHFT_6TO10_RCLK_Pin NMOS_SHFT_6TO10_SRCLK_Pin NMOS_SHFT_6TO10_SRCLR_Pin PMOS_SHFT_6TO10_SER_Pin
                           PMOS_SHFT_6TO10_NOE_Pin PMOS_SHFT_6TO10_RCLK_Pin P5V_en_Pin P3V_en_Pin
                           NMOS_SHFT_1TO5_SRCLR_Pin */
  GPIO_InitStruct.Pin = NMOS_SHFT_6TO10_RCLK_Pin|NMOS_SHFT_6TO10_SRCLK_Pin|NMOS_SHFT_6TO10_SRCLR_Pin|PMOS_SHFT_6TO10_SER_Pin
                          |PMOS_SHFT_6TO10_NOE_Pin|PMOS_SHFT_6TO10_RCLK_Pin|P5V_en_Pin|P3V_en_Pin
                          |NMOS_SHFT_1TO5_SRCLR_Pin;
  GPIO_InitStruct.Mode = GPIO_MODE_OUTPUT_PP;
  GPIO_InitStruct.Pull = GPIO_NOPULL;
  GPIO_InitStruct.Speed = GPIO_SPEED_FREQ_LOW;
  HAL_GPIO_Init(GPIOD, &GPIO_InitStruct);

  /*Configure GPIO pins : MUX_D5_Pin MUX_D4_Pin MUX_D3_Pin MUX_D2_Pin
                           MUX_D1_Pin */
  GPIO_InitStruct.Pin = MUX_D5_Pin|MUX_D4_Pin|MUX_D3_Pin|MUX_D2_Pin
                          |MUX_D1_Pin;
  GPIO_InitStruct.Mode = GPIO_MODE_INPUT;
  GPIO_InitStruct.Pull = GPIO_NOPULL;
  HAL_GPIO_Init(GPIOG, &GPIO_InitStruct);

  /*Configure GPIO pin : NMOS_SHFT_1TO5_NOE_Pin */
  GPIO_InitStruct.Pin = NMOS_SHFT_1TO5_NOE_Pin;
  GPIO_InitStruct.Mode = GPIO_MODE_OUTPUT_PP;
  GPIO_InitStruct.Pull = GPIO_NOPULL;
  GPIO_InitStruct.Speed = GPIO_SPEED_FREQ_LOW;
  HAL_GPIO_Init(NMOS_SHFT_1TO5_NOE_GPIO_Port, &GPIO_InitStruct);

}

void StartDefaultTask(void const * argument)
{
  /* init code for USB_DEVICE */
  MX_USB_DEVICE_Init();

  /* init code for LWIP */
  MX_LWIP_Init();
  /* USER CODE BEGIN 5 */
  extern struct netif gnetif;
  status = HAL_ETH_ReadPHYRegister(&heth,PHY_BSR, 0x10, &Reg_Val);
  if((Reg_Val & 1UL) == 0UL){
    printf("TCP SERVER WILL START AFTER CABLE WILL BE PLUGED IN!!!\n\r");
  }
  else{
    printf("TCP SERVER STARTED\n\r");
    server_is_running_flag = 1;
    dhcp_start(&gnetif);
    tcp_server_init();
  }

  printf("TCP Server started\n");
  printf("DELAY 25us\n");
  _2500_ns_delay(40);
  printf("BOOTED FROM DFU\n");
  HAL_CAN_Start(&hcan1);
  HAL_CAN_ActivateNotification(&hcan1, CAN_IT_RX_FIFO0_MSG_PENDING);
  CanTxHeader.DLC = 1;
  CanTxHeader.ExtId = 0;
  CanTxHeader.IDE = CAN_ID_STD;
  CanTxHeader.RTR = CAN_RTR_DATA;
  CanTxHeader.StdId = 0x65;
  CanTxHeader.TransmitGlobalTime = DISABLE;

  CanTxData[0] = 0x3d;

  HAL_DAC_SetValue(&hdac, DAC_CHANNEL_1, DAC_ALIGN_12B_R, 0x0);
  HAL_GPIO_WritePin(MUXes_1to5_nEN_GPIO_Port, MUXes_1to5_nEN_Pin, GPIO_PIN_RESET);
  HAL_GPIO_WritePin(MUXes_1to5_A0_GPIO_Port, MUXes_1to5_A0_Pin, GPIO_PIN_RESET);
  HAL_GPIO_WritePin(MUXes_1to5_A1_GPIO_Port, MUXes_1to5_A1_Pin, GPIO_PIN_RESET);
  HAL_GPIO_WritePin(MUXes_1to5_A2_GPIO_Port, MUXes_1to5_A2_Pin, GPIO_PIN_RESET);
  HAL_GPIO_WritePin(NMOS_SHFT_1TO5_SRCLR_GPIO_Port, NMOS_SHFT_1TO5_SRCLR_Pin, GPIO_PIN_RESET);
  HAL_GPIO_WritePin(NMOS_SHFT_1TO5_NOE_GPIO_Port, NMOS_SHFT_1TO5_NOE_Pin, GPIO_PIN_RESET);

  HAL_GPIO_WritePin(MUXes_6to10_nEN_GPIO_Port, MUXes_6to10_nEN_Pin, GPIO_PIN_RESET);
  HAL_GPIO_WritePin(MUXes_6to10_A0_GPIO_Port, MUXes_6to10_A0_Pin, GPIO_PIN_RESET);
  HAL_GPIO_WritePin(MUXes_6to10_A1_GPIO_Port, MUXes_6to10_A1_Pin, GPIO_PIN_RESET);
  HAL_GPIO_WritePin(MUXes_6to10_A2_GPIO_Port, MUXes_6to10_A2_Pin, GPIO_PIN_RESET);
  HAL_GPIO_WritePin(NMOS_SHFT_6TO10_SRCLR_GPIO_Port, NMOS_SHFT_6TO10_SRCLR_Pin, GPIO_PIN_RESET);
  HAL_GPIO_WritePin(NMOS_SHFT_6TO10_NOE_GPIO_Port, NMOS_SHFT_6TO10_NOE_Pin, GPIO_PIN_RESET);
  /* Infinite loop */
  for(;;)
  {
    HAL_GPIO_TogglePin(STATUS_LED_GPIO_Port, STATUS_LED_Pin);
    //HAL_CAN_AddTxMessage(&hcan1, &CanTxHeader, CanTxData, &CanTxMailbox);

    if(server_is_running_flag == 0){
      status = HAL_ETH_ReadPHYRegister(&heth,PHY_BSR, 0x10, &Reg_Val);
      if((Reg_Val & 1UL) == 0UL){
        printf("TCP SERVER WILL START AFTER CABLE WILL BE PLUGED IN!!!\n\r");
      }
      else{
        printf("TCP SERVER STARTED\n\r");
        server_is_running_flag = 1;
        dhcp_start(&gnetif);
        tcp_server_init();
      }
    }

    osDelay(500);
  }
  /* USER CODE END 5 */
}

void HAL_TIM_PeriodElapsedCallback(TIM_HandleTypeDef *htim)
{
  /* USER CODE BEGIN Callback 0 */
  if (htim->Instance == TIM11) {
    _us_tick++;
  }

  /* USER CODE END Callback 0 */
  if (htim->Instance == TIM14) {
    HAL_IncTick();
  }
}

void Error_Handler(void)
{
  __disable_irq();
  while (1)
  {
  }
}
